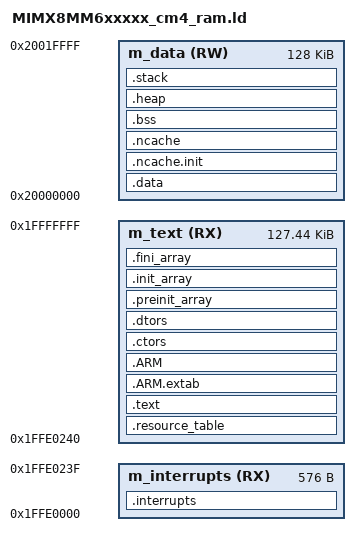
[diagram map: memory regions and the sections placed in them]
ENTRY(Reset_Handler)

HEAP_SIZE  = DEFINED(__heap_size__)  ? __heap_size__  : 0x0400;
STACK_SIZE = DEFINED(__stack_size__) ? __stack_size__ : 0x0400;

MEMORY
{
  m_interrupts (RX) : ORIGIN = 0x1FFE0000, LENGTH = 0x00000240
  m_text       (RX) : ORIGIN = 0x1FFE0240, LENGTH = 0x0001FDC0
  m_data       (RW) : ORIGIN = 0x20000000, LENGTH = 0x00020000
}

SECTIONS
{
  .interrupts :
  {
    __VECTOR_TABLE = .;
    __Vectors = .;
    . = ALIGN(4);
    KEEP(*(.isr_vector))
    . = ALIGN(4);
  } > m_interrupts

  .resource_table :
  {
    . = ALIGN(8);
    KEEP(*(.resource_table))
    . = ALIGN(8);
  } > m_text

  .text :
  {
    . = ALIGN(4);
    *(.text)
    *(.text*)
    *(.rodata)
    *(.rodata*)
    *(.glue_7)
    *(.glue_7t)
    *(.eh_frame)
    KEEP(*(.init))
    KEEP(*(.fini))
    . = ALIGN(4);
  } > m_text

  .ARM.extab : { *(.ARM.extab* .gnu.linkonce.armextab.*) } > m_text

  .ARM :
  {
    __exidx_start = .;
    *(.ARM.exidx*)
    __exidx_end = .;
  } > m_text

  .ctors :
  {
    __CTOR_LIST__ = .;
    KEEP(*crtbegin.o(.ctors))
    KEEP(*crtbegin?.o(.ctors))
    KEEP(*(EXCLUDE_FILE(*crtend?.o *crtend.o) .ctors))
    KEEP(*(SORT(.ctors.*)))
    KEEP(*(.ctors))
    __CTOR_END__ = .;
  } > m_text

  .dtors :
  {
    __DTOR_LIST__ = .;
    KEEP(*crtbegin.o(.dtors))
    KEEP(*crtbegin?.o(.dtors))
    KEEP(*(EXCLUDE_FILE(*crtend?.o *crtend.o) .dtors))
    KEEP(*(SORT(.dtors.*)))
    KEEP(*(.dtors))
    __DTOR_END__ = .;
  } > m_text

  .preinit_array :
  {
    PROVIDE_HIDDEN(__preinit_array_start = .);
    KEEP(*(.preinit_array*))
    PROVIDE_HIDDEN(__preinit_array_end = .);
  } > m_text

  .init_array :
  {
    PROVIDE_HIDDEN(__init_array_start = .);
    KEEP(*(SORT(.init_array.*)))
    KEEP(*(.init_array*))
    PROVIDE_HIDDEN(__init_array_end = .);
  } > m_text

  .fini_array :
  {
    PROVIDE_HIDDEN(__fini_array_start = .);
    KEEP(*(SORT(.fini_array.*)))
    KEEP(*(.fini_array*))
    PROVIDE_HIDDEN(__fini_array_end = .);
  } > m_text

  __etext = .;
  __DATA_ROM = .;

  .data : AT(__DATA_ROM)
  {
    . = ALIGN(4);
    __DATA_RAM = .;
    __data_start__ = .;
    *(.data)
    *(.data*)
    KEEP(*(.jcr*))
    . = ALIGN(4);
    __data_end__ = .;
  } > m_data

  __CACHE_REGION_START = ORIGIN(m_interrupts);
  __CACHE_REGION_SIZE = 0;
  __NDATA_ROM = __DATA_ROM + SIZEOF(.data);

  .ncache.init : AT(__NDATA_ROM)
  {
    __noncachedata_start__ = .;
    *(NonCacheable.init)
    . = ALIGN(4);
    __noncachedata_init_end__ = .;
  } > m_data

  . = __noncachedata_init_end__;
  .ncache :
  {
    *(NonCacheable)
    . = ALIGN(4);
    __noncachedata_end__ = .;
  } > m_data

  __DATA_END = __DATA_ROM + (__data_end__ - __data_start__);
  text_end = ORIGIN(m_text) + LENGTH(m_text);
  ASSERT(__DATA_END <= text_end, "region m_text overflowed with text and data")

  .bss :
  {
    . = ALIGN(4);
    __START_BSS = .;
    __bss_start__ = .;
    *(.bss)
    *(.bss*)
    *(COMMON)
    . = ALIGN(4);
    __bss_end__ = .;
    __END_BSS = .;
  } > m_data

  .heap :
  {
    . = ALIGN(8);
    __end__ = .;
    PROVIDE(end = .);
    __HeapBase = .;
    . += HEAP_SIZE;
    __HeapLimit = .;
    __heap_limit = .;
  } > m_data

  .stack :
  {
    . = ALIGN(8);
    . += STACK_SIZE;
  } > m_data

  __StackTop = ORIGIN(m_data) + LENGTH(m_data);
  __StackLimit = __StackTop - STACK_SIZE;
  PROVIDE(__stack = __StackTop);

  .ARM.attributes 0 : { *(.ARM.attributes) }

  ASSERT(__StackLimit >= __HeapLimit, "region m_data overflowed with stack and heap")
}
